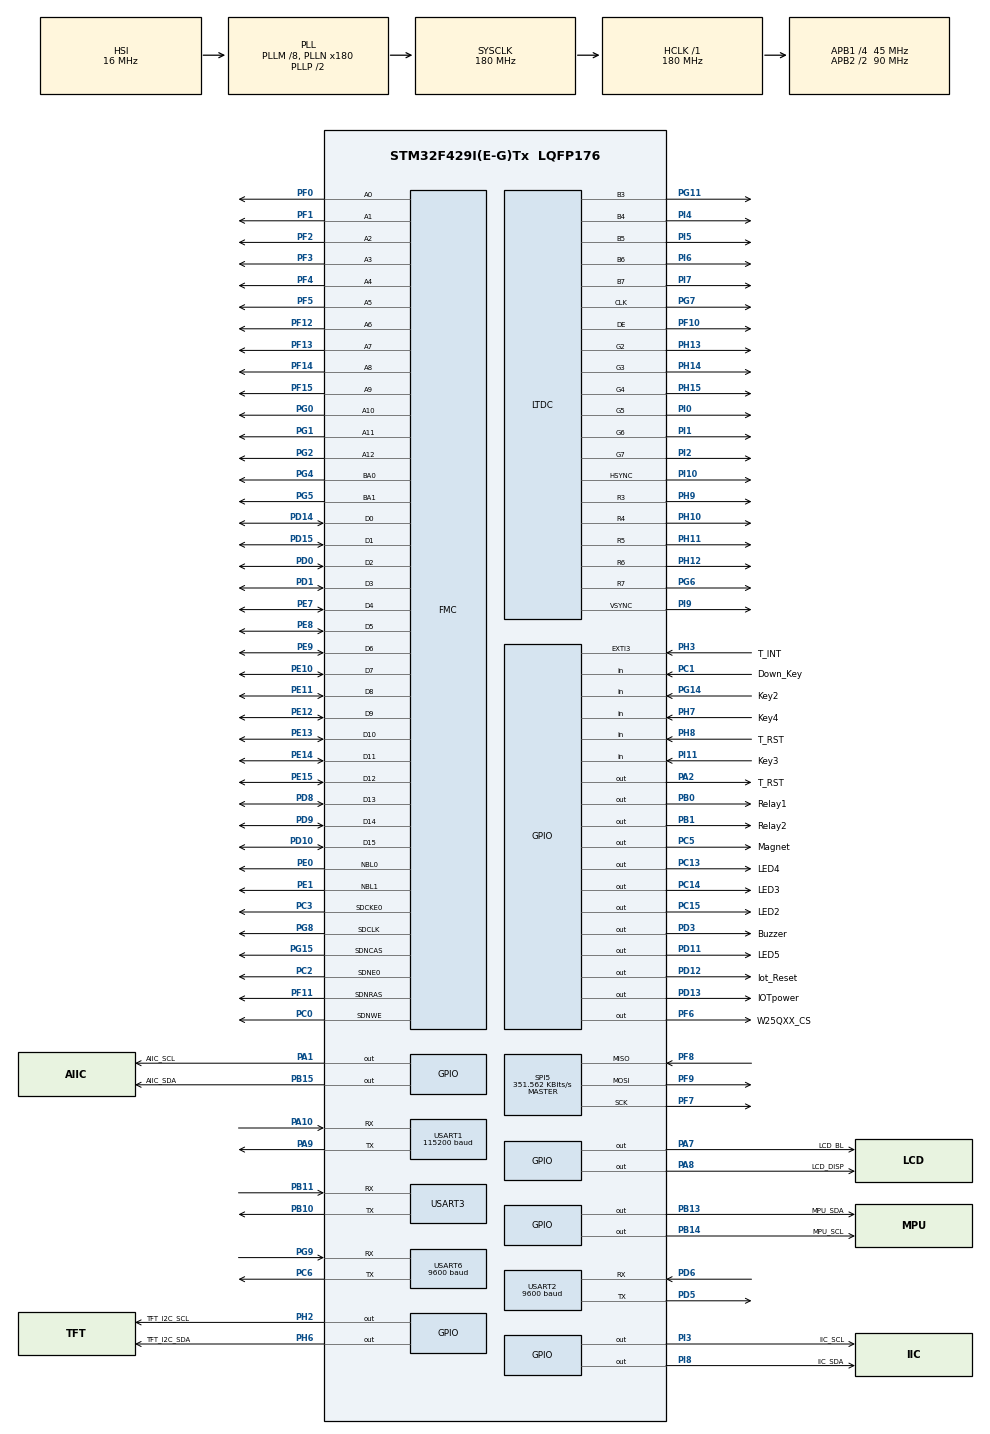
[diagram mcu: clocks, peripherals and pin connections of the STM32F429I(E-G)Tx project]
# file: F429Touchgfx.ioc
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DMA2D.ColorMode=DMA2D_OUTPUT_RGB565
DMA2D.Mode=DMA2D_R2M
Dma.Request0=USART3_RX
Dma.Request1=USART6_RX
Dma.USART3_RX.0.Direction=DMA_PERIPH_TO_MEMORY
Dma.USART3_RX.0.FIFOMode=DMA_FIFOMODE_DISABLE
Dma.USART3_RX.0.Instance=DMA1_Stream1
Dma.USART3_RX.0.MemDataAlignment=DMA_MDATAALIGN_BYTE
Dma.USART3_RX.0.MemInc=DMA_MINC_ENABLE
Dma.USART3_RX.0.Mode=DMA_NORMAL
Dma.USART3_RX.0.PeriphDataAlignment=DMA_PDATAALIGN_BYTE
Dma.USART3_RX.0.PeriphInc=DMA_PINC_DISABLE
Dma.USART3_RX.0.Priority=DMA_PRIORITY_LOW
Dma.USART6_RX.1.Direction=DMA_PERIPH_TO_MEMORY
Dma.USART6_RX.1.FIFOMode=DMA_FIFOMODE_DISABLE
Dma.USART6_RX.1.Instance=DMA2_Stream1
Dma.USART6_RX.1.MemDataAlignment=DMA_MDATAALIGN_BYTE
Dma.USART6_RX.1.MemInc=DMA_MINC_ENABLE
Dma.USART6_RX.1.Mode=DMA_NORMAL
Dma.USART6_RX.1.PeriphDataAlignment=DMA_PDATAALIGN_BYTE
Dma.USART6_RX.1.PeriphInc=DMA_PINC_DISABLE
Dma.USART6_RX.1.Priority=DMA_PRIORITY_LOW
FMC.CASLatency1=FMC_SDRAM_CAS_LATENCY_3
FMC.ColumnBitsNumber1=FMC_SDRAM_COLUMN_BITS_NUM_9
FMC.ExitSelfRefreshDelay1=8
FMC.LoadToActiveDelay1=2
FMC.RCDDelay1=2
FMC.RPDelay1=2
FMC.RPDelay2=2
FMC.ReadBurst1=FMC_SDRAM_RBURST_ENABLE
FMC.ReadBurst2=FMC_SDRAM_RBURST_ENABLE
FMC.ReadPipeDelay1=FMC_SDRAM_RPIPE_DELAY_1
FMC.ReadPipeDelay2=FMC_SDRAM_RPIPE_DELAY_1
FMC.RowCycleDelay1=6
FMC.RowCycleDelay2=6
FMC.SDClockPeriod1=FMC_SDRAM_CLOCK_PERIOD_2
FMC.SDClockPeriod2=FMC_SDRAM_CLOCK_PERIOD_2
FMC.SelfRefreshTime1=6
FMC.WriteRecoveryTime1=4
FREERTOS.Tasks01=defaultTask,0,2048,StartDefaultTask,Default,NULL,Dynamic,NULL,NULL;ATParse,-2,512,StartATParse,Default,NULL,Dynamic,NULL,NULL;ATFram,0,256,StartATFram,Default,NULL,Dynamic,NULL,NULL;ATSend,-2,256,StartATSend,Default,NULL,Dynamic,NULL,NULL;SensorCollect,-2,128,StartSensorCollect,Default,NULL,Dynamic,NULL,NULL
LTDC.ActiveH=480
LTDC.ActiveW=800
LTDC.Alpha_L0=0xff
LTDC.FBStartAdress_L0=0xc0000000
LTDC.HBP=88
LTDC.HFP=40
LTDC.HSync=48
LTDC.ImageHeight_L0=480
LTDC.ImageWidth_L0=800
LTDC.Layers=0
LTDC.PixelFormat_L0=LTDC_PIXEL_FORMAT_RGB565
LTDC.VBP=32
LTDC.VFP=13
LTDC.VSync=3
LTDC.WindowX1_L0=800
LTDC.WindowY1_L0=480
Mcu.Family=STM32F4
Mcu.Name=STM32F429I(E-G)Tx
Mcu.Package=LQFP176
NVIC.DMA1_Stream1_IRQn=true\:5\:0\:true\:false\:true\:false\:false\:true
NVIC.DMA2D_IRQn=true\:5\:0\:true\:false\:true\:false\:true\:true
NVIC.DMA2_Stream1_IRQn=true\:4\:0\:true\:false\:true\:false\:false\:true
NVIC.EXTI3_IRQn=true\:5\:0\:true\:false\:true\:false\:true\:true
NVIC.FLASH_IRQn=true\:5\:0\:true\:false\:true\:false\:true\:true
NVIC.FMC_IRQn=true\:5\:0\:true\:false\:true\:false\:true\:true
NVIC.FPU_IRQn=true\:5\:0\:true\:false\:true\:false\:false\:false
NVIC.LTDC_ER_IRQn=true\:6\:0\:true\:false\:true\:false\:true\:true
NVIC.LTDC_IRQn=true\:6\:0\:true\:false\:true\:false\:true\:true
NVIC.PVD_IRQn=true\:5\:0\:true\:false\:true\:false\:true\:true
NVIC.PriorityGroup=NVIC_PRIORITYGROUP_4
NVIC.RCC_IRQn=true\:5\:0\:true\:false\:true\:false\:false\:false
NVIC.SPI5_IRQn=true\:5\:0\:true\:false\:true\:false\:true\:true
NVIC.TIM1_UP_TIM10_IRQn=true\:0\:0\:false\:false\:true\:false\:false\:true
NVIC.TIM8_UP_TIM13_IRQn=true\:5\:0\:false\:false\:true\:true\:true\:true
NVIC.TimeBase=TIM1_UP_TIM10_IRQn
NVIC.TimeBaseIP=TIM1
NVIC.USART1_IRQn=true\:6\:0\:true\:false\:true\:false\:true\:true
NVIC.USART2_IRQn=true\:6\:0\:true\:false\:true\:false\:true\:true
NVIC.USART3_IRQn=true\:6\:0\:true\:false\:true\:false\:true\:true
NVIC.USART6_IRQn=true\:6\:0\:true\:false\:true\:false\:true\:true
PA1.GPIO_Label=AIIC_SCL
PA1.GPIO_PuPd=GPIO_PULLUP
PA1.GPIO_Speed=GPIO_SPEED_FREQ_HIGH
PA1.PinState=GPIO_PIN_SET
PA1.Signal=GPIO_Output
PA10.Mode=Asynchronous
PA10.Signal=USART1_RX
PA13.Mode=Serial_Wire
PA13.Signal=SYS_JTMS-SWDIO
PA14.Mode=Serial_Wire
PA14.Signal=SYS_JTCK-SWCLK
PA2.GPIO_Label=T_RST
PA2.GPIO_PuPd=GPIO_PULLUP
PA2.PinState=GPIO_PIN_SET
PA2.Signal=GPIO_Output
PA7.GPIO_Label=LCD_BL
PA7.GPIO_PuPd=GPIO_PULLUP
PA7.PinState=GPIO_PIN_SET
PA7.Signal=GPIO_Output
PA8.GPIO_Label=LCD_DISP
PA8.GPIO_PuPd=GPIO_PULLUP
PA8.PinState=GPIO_PIN_SET
PA8.Signal=GPIO_Output
PA9.Mode=Asynchronous
PA9.Signal=USART1_TX
PB0.GPIO_Label=Relay1
PB0.PinState=GPIO_PIN_SET
PB0.Signal=GPIO_Output
PB1.GPIO_Label=Relay2
PB1.PinState=GPIO_PIN_SET
PB1.Signal=GPIO_Output
PB10.Mode=Asynchronous
PB10.Signal=USART3_TX
PB11.GPIO_PuPd=GPIO_PULLUP
PB11.Mode=Asynchronous
PB11.Signal=USART3_RX
PB13.GPIO_Label=MPU_SDA
PB13.GPIO_PuPd=GPIO_PULLUP
PB13.PinState=GPIO_PIN_SET
PB13.Signal=GPIO_Output
PB14.GPIO_Label=MPU_SCL
PB14.GPIO_PuPd=GPIO_PULLUP
PB14.PinState=GPIO_PIN_SET
PB14.Signal=GPIO_Output
PB15.GPIO_Label=AIIC_SDA
PB15.GPIO_PuPd=GPIO_PULLUP
PB15.PinState=GPIO_PIN_SET
PB15.Signal=GPIO_Output
PC0.Signal=FMC_SDNWE
PC1.GPIO_Label=Down_Key
PC1.GPIO_PuPd=GPIO_PULLUP
PC1.Signal=GPIO_Input
PC13.GPIO_Label=LED4
PC13.GPIO_PuPd=GPIO_PULLUP
PC13.PinState=GPIO_PIN_SET
PC13.Signal=GPIO_Output
PC14/OSC32_IN.GPIO_Label=LED3
PC14/OSC32_IN.GPIO_PuPd=GPIO_PULLUP
PC14/OSC32_IN.PinState=GPIO_PIN_SET
PC14/OSC32_IN.Signal=GPIO_Output
PC15/OSC32_OUT.GPIO_Label=LED2
PC15/OSC32_OUT.GPIO_PuPd=GPIO_PULLUP
PC15/OSC32_OUT.PinState=GPIO_PIN_SET
PC15/OSC32_OUT.Signal=GPIO_Output
PC2.Mode=SdramChipSelect1_1
PC2.Signal=FMC_SDNE0
PC3.Mode=SdramChipSelect1_1
PC3.Signal=FMC_SDCKE0
PC5.GPIO_Label=Magnet
PC5.GPIO_PuPd=GPIO_PULLDOWN
PC5.PinState=GPIO_PIN_RESET
PC5.Signal=GPIO_Output
PC6.Mode=Asynchronous
PC6.Signal=USART6_TX
PD0.Signal=FMC_D2_DA2
PD1.Signal=FMC_D3_DA3
PD10.Signal=FMC_D15_DA15
PD11.GPIO_Label=LED5
PD11.GPIO_PuPd=GPIO_PULLUP
PD11.PinState=GPIO_PIN_SET
PD11.Signal=GPIO_Output
PD12.GPIO_Label=Iot_Reset
PD12.GPIO_PuPd=GPIO_PULLUP
PD12.PinState=GPIO_PIN_SET
PD12.Signal=GPIO_Output
PD13.GPIO_Label=IOTpower
PD13.GPIO_PuPd=GPIO_PULLUP
PD13.PinState=GPIO_PIN_SET
PD13.Signal=GPIO_Output
PD14.Signal=FMC_D0_DA0
PD15.Signal=FMC_D1_DA1
PD3.GPIO_Label=Buzzer
PD3.GPIO_PuPd=GPIO_PULLUP
PD3.Signal=GPIO_Output
PD5.Mode=Asynchronous
PD5.Signal=USART2_TX
PD6.GPIO_PuPd=GPIO_PULLUP
PD6.Mode=Asynchronous
PD6.Signal=USART2_RX
PD8.Signal=FMC_D13_DA13
PD9.Signal=FMC_D14_DA14
PE0.Signal=FMC_NBL0
PE1.Signal=FMC_NBL1
PE10.Signal=FMC_D7_DA7
PE11.Signal=FMC_D8_DA8
PE12.Signal=FMC_D9_DA9
PE13.Signal=FMC_D10_DA10
PE14.Signal=FMC_D11_DA11
PE15.Signal=FMC_D12_DA12
PE7.Signal=FMC_D4_DA4
PE8.Signal=FMC_D5_DA5
PE9.Signal=FMC_D6_DA6
PF0.Signal=FMC_A0
PF1.Signal=FMC_A1
PF10.Mode=RGB565
PF10.Signal=LTDC_DE
PF11.Signal=FMC_SDNRAS
PF12.Signal=FMC_A6
PF13.Signal=FMC_A7
PF14.Signal=FMC_A8
PF15.Signal=FMC_A9
PF2.Signal=FMC_A2
PF3.Signal=FMC_A3
PF4.Signal=FMC_A4
PF5.Signal=FMC_A5
PF6.GPIO_Label=W25QXX_CS
PF6.GPIO_PuPd=GPIO_PULLUP
PF6.GPIO_Speed=GPIO_SPEED_FREQ_HIGH
PF6.Signal=GPIO_Output
PF7.Mode=Full_Duplex_Master
PF7.Signal=SPI5_SCK
PF8.Mode=Full_Duplex_Master
PF8.Signal=SPI5_MISO
PF9.Mode=Full_Duplex_Master
PF9.Signal=SPI5_MOSI
PG0.Signal=FMC_A10
PG1.Signal=FMC_A11
PG11.Mode=RGB565
PG11.Signal=LTDC_B3
PG14.GPIO_Label=Key2
PG14.GPIO_PuPd=GPIO_PULLUP
PG14.Signal=GPIO_Input
PG15.Signal=FMC_SDNCAS
PG2.Signal=FMC_A12
PG4.Signal=FMC_A14_BA0
PG5.Signal=FMC_A15_BA1
PG6.Mode=RGB565
PG6.Signal=LTDC_R7
PG7.Mode=RGB565
PG7.Signal=LTDC_CLK
PG8.Signal=FMC_SDCLK
PG9.GPIO_PuPd=GPIO_PULLUP
PG9.Mode=Asynchronous
PG9.Signal=USART6_RX
PH0/OSC_IN.Mode=HSE-External-Oscillator
PH0/OSC_IN.Signal=RCC_OSC_IN
PH1/OSC_OUT.Mode=HSE-External-Oscillator
PH1/OSC_OUT.Signal=RCC_OSC_OUT
PH10.Mode=RGB565
PH10.Signal=LTDC_R4
PH11.Mode=RGB565
PH11.Signal=LTDC_R5
PH12.Mode=RGB565
PH12.Signal=LTDC_R6
PH13.Mode=RGB565
PH13.Signal=LTDC_G2
PH14.Mode=RGB565
PH14.Signal=LTDC_G3
PH15.Mode=RGB565
PH15.Signal=LTDC_G4
PH2.GPIO_Label=TFT_I2C_SCL
PH2.GPIO_PuPd=GPIO_PULLUP
PH2.PinState=GPIO_PIN_SET
PH2.Signal=GPIO_Output
PH3.GPIO_Label=T_INT
PH3.Signal=GPXTI3
PH6.GPIO_Label=TFT_I2C_SDA
PH6.GPIO_PuPd=GPIO_PULLUP
PH6.PinState=GPIO_PIN_SET
PH6.Signal=GPIO_Output
PH7.GPIO_Label=Key4
PH7.GPIO_PuPd=GPIO_PULLUP
PH7.Signal=GPIO_Input
PH8.GPIO_Label=T_RST
PH8.GPIO_PuPd=GPIO_PULLUP
PH8.Signal=GPIO_Input
PH9.Mode=RGB565
PH9.Signal=LTDC_R3
PI0.Mode=RGB565
PI0.Signal=LTDC_G5
PI1.Mode=RGB565
PI1.Signal=LTDC_G6
PI10.Mode=RGB565
PI10.Signal=LTDC_HSYNC
PI11.GPIO_Label=Key3
PI11.GPIO_PuPd=GPIO_PULLUP
PI11.Signal=GPIO_Input
PI2.Mode=RGB565
PI2.Signal=LTDC_G7
PI3.GPIO_Label=IIC_SCL
PI3.GPIO_PuPd=GPIO_PULLUP
PI3.PinState=GPIO_PIN_SET
PI3.Signal=GPIO_Output
PI4.Mode=RGB565
PI4.Signal=LTDC_B4
PI5.Mode=RGB565
PI5.Signal=LTDC_B5
PI6.Mode=RGB565
PI6.Signal=LTDC_B6
PI7.Mode=RGB565
PI7.Signal=LTDC_B7
PI8.GPIO_Label=IIC_SDA
PI8.GPIO_PuPd=GPIO_PULLUP
PI8.PinState=GPIO_PIN_SET
PI8.Signal=GPIO_Output
PI9.Mode=RGB565
PI9.Signal=LTDC_VSYNC
ProjectManager.HeapSize=0x200
ProjectManager.StackSize=0x400
ProjectManager.TargetToolchain=MDK-ARM V5.27
RCC.48MHZClocksFreq_Value=90000000
RCC.AHBFreq_Value=180000000
RCC.APB1CLKDivider=RCC_HCLK_DIV4
RCC.APB1Freq_Value=45000000
RCC.APB1TimFreq_Value=90000000
RCC.APB2CLKDivider=RCC_HCLK_DIV2
RCC.APB2Freq_Value=90000000
RCC.APB2TimFreq_Value=180000000
RCC.CortexFreq_Value=180000000
RCC.HCLKFreq_Value=180000000
RCC.HSE_VALUE=25000000
RCC.HSI_VALUE=16000000
RCC.LSE_VALUE=32768
RCC.PLLM=8
RCC.PLLN=180
RCC.PLLSAIN=50
RCC.SYSCLKFreq_VALUE=180000000
RCC.SYSCLKSource=RCC_SYSCLKSOURCE_PLLCLK
RCC.VCOOutputFreq_Value=360000000
SH.FMC_A0.0=FMC_A0,13b-sda1
SH.FMC_A1.0=FMC_A1,13b-sda1
SH.FMC_A10.0=FMC_A10,13b-sda1
SH.FMC_A11.0=FMC_A11,13b-sda1
SH.FMC_A12.0=FMC_A12,13b-sda1
SH.FMC_A14_BA0.0=FMC_BA0,FourSdramBanks1
SH.FMC_A15_BA1.0=FMC_BA1,FourSdramBanks1
SH.FMC_A2.0=FMC_A2,13b-sda1
SH.FMC_A3.0=FMC_A3,13b-sda1
SH.FMC_A4.0=FMC_A4,13b-sda1
SH.FMC_A5.0=FMC_A5,13b-sda1
SH.FMC_A6.0=FMC_A6,13b-sda1
SH.FMC_A7.0=FMC_A7,13b-sda1
SH.FMC_A8.0=FMC_A8,13b-sda1
SH.FMC_A9.0=FMC_A9,13b-sda1
SH.FMC_D0_DA0.0=FMC_D0,sd-16b-d1
SH.FMC_D10_DA10.0=FMC_D10,sd-16b-d1
SH.FMC_D11_DA11.0=FMC_D11,sd-16b-d1
SH.FMC_D12_DA12.0=FMC_D12,sd-16b-d1
SH.FMC_D13_DA13.0=FMC_D13,sd-16b-d1
SH.FMC_D14_DA14.0=FMC_D14,sd-16b-d1
SH.FMC_D15_DA15.0=FMC_D15,sd-16b-d1
SH.FMC_D1_DA1.0=FMC_D1,sd-16b-d1
SH.FMC_D2_DA2.0=FMC_D2,sd-16b-d1
SH.FMC_D3_DA3.0=FMC_D3,sd-16b-d1
SH.FMC_D4_DA4.0=FMC_D4,sd-16b-d1
SH.FMC_D5_DA5.0=FMC_D5,sd-16b-d1
SH.FMC_D6_DA6.0=FMC_D6,sd-16b-d1
SH.FMC_D7_DA7.0=FMC_D7,sd-16b-d1
SH.FMC_D8_DA8.0=FMC_D8,sd-16b-d1
SH.FMC_D9_DA9.0=FMC_D9,sd-16b-d1
SH.FMC_NBL0.0=FMC_NBL0,Sd2ByteEnable1
SH.FMC_NBL1.0=FMC_NBL1,Sd2ByteEnable1
SH.FMC_SDCLK.0=FMC_SDCLK,13b-sda1
SH.FMC_SDNCAS.0=FMC_SDNCAS,13b-sda1
SH.FMC_SDNRAS.0=FMC_SDNRAS,13b-sda1
SH.FMC_SDNWE.0=FMC_SDNWE,13b-sda1
SPI5.BaudRatePrescaler=SPI_BAUDRATEPRESCALER_256
SPI5.CLKPhase=SPI_PHASE_2EDGE
SPI5.CLKPolarity=SPI_POLARITY_HIGH
SPI5.CalculateBaudRate=351.562 KBits/s
SPI5.Direction=SPI_DIRECTION_2LINES
SPI5.Mode=SPI_MODE_MASTER
SPI5.VirtualType=VM_MASTER
STMicroelectronics.X-CUBE-TOUCHGFX.4.18.0.ApplicationCcGraphicsJjApplication=TouchGFXOoGenerator
STMicroelectronics.X-CUBE-TOUCHGFX.4.18.0.tgfx_address1=0xC0000000
STMicroelectronics.X-CUBE-TOUCHGFX.4.18.0.tgfx_address2=0xC00BB800
STMicroelectronics.X-CUBE-TOUCHGFX.4.18.0.tgfx_buffering_strategy=Double
STMicroelectronics.X-CUBE-TOUCHGFX.4.18.0.tgfx_display_interface=disp_ltdc
STMicroelectronics.X-CUBE-TOUCHGFX.4.18.0.tgfx_hardware_accelerator=dma_2d
STMicroelectronics.X-CUBE-TOUCHGFX.4.18.0.tgfx_location=By Address
STMicroelectronics.X-CUBE-TOUCHGFX.4.18.0.tgfx_vsync=vsync_ltdc
TIM13.AutoReloadPreload=TIM_AUTORELOAD_PRELOAD_ENABLE
TIM13.Period=10000-1
TIM13.Prescaler=9000-1
TIM14.AutoReloadPreload=TIM_AUTORELOAD_PRELOAD_ENABLE
TIM14.Prescaler=90-1
USART1.BaudRate=115200
USART1.VirtualMode=VM_ASYNC
USART2.BaudRate=9600
USART2.VirtualMode=VM_ASYNC
USART3.VirtualMode=VM_ASYNC
USART6.BaudRate=9600
USART6.VirtualMode=VM_ASYNC
VP_CRC_VS_CRC.Mode=CRC_Activate
VP_DMA2D_VS_DMA2D.Mode=DMA2D_Activate
VP_FREERTOS_VS_CMSIS_V1.Mode=CMSIS_V1
VP_STMicroelectronics.X-CUBE-TOUCHGFX_VS_GraphicsJjApplication_4.18.0.Mode=GraphicsJjApplication
VP_SYS_VS_tim1.Mode=TIM1
VP_TIM13_VS_ClockSourceINT.Mode=Enable_Timer
VP_TIM14_VS_ClockSourceINT.Mode=Enable_Timer
board=custom

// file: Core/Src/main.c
/* USER CODE BEGIN Header */
/**
  ******************************************************************************
  * @file           : main.c
  * @brief          : Main program body
  ******************************************************************************
  * @attention
  *
  * <h2><center>&copy; Copyright (c) 2021 STMicroelectronics.
  * All rights reserved.</center></h2>
  *
  * This software component is licensed by ST under Ultimate Liberty license
  * SLA0044, the "License"; You may not use this file except in compliance with
  * the License. You may obtain a copy of the License at:
  *                             www.st.com/SLA0044
  *
  ******************************************************************************
  */
/* USER CODE END Header */
#include "main.h"
#include "cmsis_os.h"
#include "crc.h"
#include "dma.h"
#include "dma2d.h"
#include "ltdc.h"
#include "spi.h"
#include "tim.h"
#include "usart.h"
#include "gpio.h"
#include "fmc.h"
#include "app_touchgfx.h"

/* USER CODE BEGIN Includes */
#include "gt1151q_iic_driver.h"
#include "w25qxx.h"
//#include "MY_Bm280_Bh1750.h"
#include "24c02.h"
#include "AT.h"
#include "cJSON.h"
#include "system.h"
#include "bh1750.h"
#include "bmp280.h"
#include "mpu6050.h"
#include "mk_dht11.h"
/* USER CODE END Includes */

void SystemClock_Config(void);
void MX_FREERTOS_Init(void);

int main(void)
{

  /* MCU Configuration--------------------------------------------------------*/

  /* Reset of all peripherals, Initializes the Flash interface and the Systick. */
  HAL_Init();

  /* Configure the system clock */
  SystemClock_Config();

  /* Initialize all configured peripherals */
  MX_GPIO_Init();
  MX_DMA_Init();
  MX_DMA2D_Init();
  MX_FMC_Init();
  MX_SPI5_Init();
  MX_USART1_UART_Init();
  MX_CRC_Init();
  MX_LTDC_Init();
  MX_USART2_UART_Init();
  MX_USART3_UART_Init();
  MX_USART6_UART_Init();
  MX_TIM14_Init();
  MX_TIM13_Init();
  MX_TouchGFX_Init();
  /* USER CODE BEGIN 2 */
	HAL_TIM_Base_Start_IT(&htim13);
	GT1151_Init();
	W25QXX_Init();

	bh1750_start();
	bmp280_start();
//	mpu6050_start();

	AT24CXX_Init();
  ATFormInit();

	while(AT24CXX_Check())	//检测不到24c02
	{
		printf("\r\n检测不到AT24C02：\r\n");
		delay_xms(500);
		HAL_GPIO_TogglePin(LED2_GPIO_Port, LED2_Pin);
	}

  /* USER CODE END 2 */

  /* Call init function for freertos objects (in freertos.c) */
  MX_FREERTOS_Init();
  /* Start scheduler */
  osKernelStart();

  /* We should never get here as control is now taken by the scheduler */
  /* Infinite loop */
  while (1)
  {

  }
}

void SystemClock_Config(void)
{
  RCC_OscInitTypeDef RCC_OscInitStruct = {0};
  RCC_ClkInitTypeDef RCC_ClkInitStruct = {0};
  RCC_PeriphCLKInitTypeDef PeriphClkInitStruct = {0};

  /** Configure the main internal regulator output voltage
  */
  __HAL_RCC_PWR_CLK_ENABLE();
  __HAL_PWR_VOLTAGESCALING_CONFIG(PWR_REGULATOR_VOLTAGE_SCALE1);
  /** Initializes the RCC Oscillators according to the specified parameters
  * in the RCC_OscInitTypeDef structure.
  */
  RCC_OscInitStruct.OscillatorType = RCC_OSCILLATORTYPE_HSI;
  RCC_OscInitStruct.HSIState = RCC_HSI_ON;
  RCC_OscInitStruct.HSICalibrationValue = RCC_HSICALIBRATION_DEFAULT;
  RCC_OscInitStruct.PLL.PLLState = RCC_PLL_ON;
  RCC_OscInitStruct.PLL.PLLSource = RCC_PLLSOURCE_HSI;
  RCC_OscInitStruct.PLL.PLLM = 8;
  RCC_OscInitStruct.PLL.PLLN = 180;
  RCC_OscInitStruct.PLL.PLLP = RCC_PLLP_DIV2;
  RCC_OscInitStruct.PLL.PLLQ = 4;
  if (HAL_RCC_OscConfig(&RCC_OscInitStruct) != HAL_OK)
  {
    Error_Handler();
  }
  /** Activate the Over-Drive mode
  */
  if (HAL_PWREx_EnableOverDrive() != HAL_OK)
  {
    Error_Handler();
  }
  /** Initializes the CPU, AHB and APB buses clocks
  */
  RCC_ClkInitStruct.ClockType = RCC_CLOCKTYPE_HCLK|RCC_CLOCKTYPE_SYSCLK
                              |RCC_CLOCKTYPE_PCLK1|RCC_CLOCKTYPE_PCLK2;
  RCC_ClkInitStruct.SYSCLKSource = RCC_SYSCLKSOURCE_PLLCLK;
  RCC_ClkInitStruct.AHBCLKDivider = RCC_SYSCLK_DIV1;
  RCC_ClkInitStruct.APB1CLKDivider = RCC_HCLK_DIV4;
  RCC_ClkInitStruct.APB2CLKDivider = RCC_HCLK_DIV2;

  if (HAL_RCC_ClockConfig(&RCC_ClkInitStruct, FLASH_LATENCY_5) != HAL_OK)
  {
    Error_Handler();
  }
  PeriphClkInitStruct.PeriphClockSelection = RCC_PERIPHCLK_LTDC;
  PeriphClkInitStruct.PLLSAI.PLLSAIN = 50;
  PeriphClkInitStruct.PLLSAI.PLLSAIR = 2;
  PeriphClkInitStruct.PLLSAIDivR = RCC_PLLSAIDIVR_2;
  if (HAL_RCCEx_PeriphCLKConfig(&PeriphClkInitStruct) != HAL_OK)
  {
    Error_Handler();
  }
}

/* USER CODE BEGIN 4 */
#pragma import(__use_no_semihosting)
//标准库需要的支持函数
struct __FILE
{
	int handle;
};
void _ttywrch(int ch)
{
//    ch=ch;
	HAL_UART_Transmit(&huart1, (uint8_t *)&ch, 1, HAL_MAX_DELAY);
}
FILE __stdout;
//定义_sys_exit()以避免使用半主机模式
void _sys_exit(int x)
{
	x = x;
}
int fputc(int ch ,FILE *F)
{
	HAL_UART_Transmit(&huart1, (uint8_t *)&ch, 1, HAL_MAX_DELAY); //按照配置自行修改huart1
	return ch;
}
/* USER CODE END 4 */

 /**
  * @brief  Period elapsed callback in non blocking mode
  * @note   This function is called  when TIM1 interrupt took place, inside
  * HAL_TIM_IRQHandler(). It makes a direct call to HAL_IncTick() to increment
  * a global variable "uwTick" used as application time base.
  * @param  htim : TIM handle
  * @retval None
  */
void HAL_TIM_PeriodElapsedCallback(TIM_HandleTypeDef *htim)
{
  if (htim->Instance == TIM1) {
    HAL_IncTick();
  }
  /* USER CODE BEGIN Callback 1 */
	if (htim->Instance == TIM13) {
		if (++time_seconds >= 60)
        {
            time_seconds = 0;
            if (++time_minutes >= 60)
            {
                time_minutes = 0;
                if (++time_hours >= 24)
                {
                    time_hours = 0;
                }
            }
        }
  }
  /* USER CODE END Callback 1 */
}

void Error_Handler(void)
{
  __disable_irq();
  while (1)
  {
  }
}

/************************ (C) COPYRIGHT STMicroelectronics *****END OF FILE****/

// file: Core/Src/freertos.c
/* USER CODE BEGIN Header */
/**
  ******************************************************************************
  * File Name          : freertos.c
  * Description        : Code for freertos applications
  ******************************************************************************
  * @attention
  *
  * <h2><center>&copy; Copyright (c) 2021 STMicroelectronics.
  * All rights reserved.</center></h2>
  *
  * This software component is licensed by ST under Ultimate Liberty license
  * SLA0044, the "License"; You may not use this file except in compliance with
  * the License. You may obtain a copy of the License at:
  *                             www.st.com/SLA0044
  *
  ******************************************************************************
  */
/* USER CODE END Header */

#include "FreeRTOS.h"
#include "task.h"
#include "main.h"
#include "cmsis_os.h"

/* USER CODE BEGIN Includes */
#include "stdio.h"
#include "AT.h"
//#include "MY_Bm280_Bh1750.h"
#include "cJSON.h"
#include "system.h"
/* USER CODE END Includes */

/* USER CODE BEGIN Variables */
char Cjsondata[250];
/* USER CODE END Variables */
osThreadId defaultTaskHandle;
osThreadId ATParseHandle;
osThreadId ATFramHandle;
osThreadId ATSendHandle;
osThreadId SensorCollectHandle;

void StartDefaultTask(void const * argument);
void StartATParse(void const * argument);
void StartATFram(void const * argument);
void StartATSend(void const * argument);
void StartSensorCollect(void const * argument);

void MX_FREERTOS_Init(void); /* (MISRA C 2004 rule 8.1) */

/* GetIdleTaskMemory prototype (linked to static allocation support) */
void vApplicationGetIdleTaskMemory( StaticTask_t **ppxIdleTaskTCBBuffer, StackType_t **ppxIdleTaskStackBuffer, uint32_t *pulIdleTaskStackSize );

/* USER CODE BEGIN GET_IDLE_TASK_MEMORY */
static StaticTask_t xIdleTaskTCBBuffer;
static StackType_t xIdleStack[configMINIMAL_STACK_SIZE];

void vApplicationGetIdleTaskMemory( StaticTask_t **ppxIdleTaskTCBBuffer, StackType_t **ppxIdleTaskStackBuffer, uint32_t *pulIdleTaskStackSize )
{
  *ppxIdleTaskTCBBuffer = &xIdleTaskTCBBuffer;
  *ppxIdleTaskStackBuffer = &xIdleStack[0];
  *pulIdleTaskStackSize = configMINIMAL_STACK_SIZE;
  /* place for user code */
}
/* USER CODE END GET_IDLE_TASK_MEMORY */

void MX_FREERTOS_Init(void) {

  /* Create the thread(s) */
  /* definition and creation of defaultTask */
  osThreadDef(defaultTask, StartDefaultTask, osPriorityNormal, 0, 2048);
  defaultTaskHandle = osThreadCreate(osThread(defaultTask), NULL);

  /* definition and creation of ATParse */
  osThreadDef(ATParse, StartATParse, osPriorityLow, 0, 512);
  ATParseHandle = osThreadCreate(osThread(ATParse), NULL);

  /* definition and creation of ATFram */
  osThreadDef(ATFram, StartATFram, osPriorityNormal, 0, 256);
  ATFramHandle = osThreadCreate(osThread(ATFram), NULL);

  /* definition and creation of ATSend */
  osThreadDef(ATSend, StartATSend, osPriorityLow, 0, 256);
  ATSendHandle = osThreadCreate(osThread(ATSend), NULL);

  /* definition and creation of SensorCollect */
  osThreadDef(SensorCollect, StartSensorCollect, osPriorityLow, 0, 128);
  SensorCollectHandle = osThreadCreate(osThread(SensorCollect), NULL);

}

void StartDefaultTask(void const * argument)
{
  /* USER CODE BEGIN StartDefaultTask */
	MX_TouchGFX_Process();
  /* Infinite loop */
  for(;;)
  {
    osDelay(100);
  }
  /* USER CODE END StartDefaultTask */
}

void StartATParse(void const * argument)
{
  /* USER CODE BEGIN StartATParse */
  /* Infinite loop */
  for(;;)
  {
    osDelay(100);
		if(uxQueueSpacesAvailable(ATcmdQueue)==10)//队列为空
		{
			if(xSemaphoreTake(ATSchRunSemaphore,( TickType_t ) 10)==pdTRUE) //获得互斥量:上锁
			{
//				PrintIotRxData();
					char *p=NULL;
					BaseType_t xResult;
					uint32_t RXDataLength=0;
					xResult=xSemaphoreTake(ATRXCplSemaphore,pdMS_TO_TICKS(1000));
					if(xResult != pdPASS)
					{
						xSemaphoreGive(ATSchRunSemaphore);/* 释放互斥量: 开锁 */
						continue;
					}
					else
					{
						printf("接收到数据\r\n");
					}
					RXDataLength=0;
					RXDataLength  = _UART_RXBUFFSIZE - __HAL_DMA_GET_COUNTER(&_UART_DMA_HANDLE);
					UartRXBuff[RXDataLength]='\0';
					__LOG("Receive Data(length = %d):%s\r\n",RXDataLength,UartRXBuff);

					p=strstr((char *)UartRXBuff,"items");
					if(p)
					{
						strcpy(Cjsondata,p+7);
						Cjsondata[strlen(Cjsondata)-3]='\0';//字符串末尾存在\r\n两个看不见的字符
						printf("THE JSON DATA IS: \r\n%s,数据长：%d\r\n",Cjsondata,strlen(Cjsondata));
						CJSON_analysis(Cjsondata);
					}

					__HAL_DMA_DISABLE(&_UART_DMA_HANDLE);

				  xSemaphoreGive(ATSchRunSemaphore);/* 释放互斥量: 开锁 */
			}
		}
//		printf("dht temp:%d hum:%d \r\n",dht_temperature,dht_humidty);
  }
  /* USER CODE END StartATParse */
}

void StartATFram(void const * argument)
{
  /* USER CODE BEGIN StartATFram */
	HAL_GPIO_WritePin(Iot_Reset_GPIO_Port,Iot_Reset_Pin,GPIO_PIN_RESET);		//复位
	osDelay(500);
	HAL_GPIO_WritePin(Iot_Reset_GPIO_Port,Iot_Reset_Pin,GPIO_PIN_SET);
	HAL_GPIO_WritePin(IOTpower_GPIO_Port,IOTpower_Pin,GPIO_PIN_RESET);      //开机
	osDelay(2200);
	HAL_GPIO_WritePin(IOTpower_GPIO_Port,IOTpower_Pin,GPIO_PIN_SET);

	printf("联网中...");
	while(strstr(UartRXBuff,"IP")==NULL)//等待设备联网
	{
		printf(".");
		osDelay(1000);
	}
	printf("\r\n联网成功!");
	PrintIotRxData();
  /* Infinite loop */
  for(;;)
  {
    ATCommandSendScheduler();
  }
  /* USER CODE END StartATFram */
}

void StartATSend(void const * argument)
{
  /* USER CODE BEGIN StartATSend */
	static char PubParam[400];
	char * jsonRes;

	ATCommandRegister(AT,EXEXCMD,NULL);
	ATCommandRegister(MQTTCFG,WRITECMD,"\"a1wocurZ0R0.iot-as-mqtt.cn-shanghai.aliyuncs.com\",1883,\"711382|securemode=3,signmethod=hmacsha1|\",\"60\",\"M5311_1382&a1wocurZ0R0\",\"A40C776AD48B66A8DB8A5EEE517625E2DB4501B4\",1");
	ATCommandRegister(MQTTOPEN,WRITECMD,"1,1,0,0,0");
	ATCommandRegister(MQTTSUB,WRITECMD,"/sys/a1wocurZ0R0/M5311_1382/thing/service/property/set");
	ATCommandRegister(CCLK,READCMD,NULL);
  /* Infinite loop */
  for(;;)
  {
		osDelay(10000);
		osDelay(10000);
		osDelay(10000);
		while(uxQueueSpacesAvailable(ATcmdQueue)!=10)//等待队列为空
		{
			osDelay(100);
		}
		cJSON* cjson_root = NULL;
		cJSON* cjson_params = NULL;
		cjson_root =  cJSON_CreateObject();
		cjson_params  =  cJSON_CreateObject();
		cJSON_AddNumberToObject(cjson_params,"CurrentTemperature",(float)(((int)(bmp280_temperature*100))/100));
		cJSON_AddNumberToObject(cjson_params,"CurrentHumidity",(uint32_t)dht_humidty);
		cJSON_AddNumberToObject(cjson_params,"LightLux",bh1750_lux);
		cJSON_AddNumberToObject(cjson_params,"Atmosphere",(uint32_t)bmp280_pressure);
//		cJSON_AddNumberToObject(cjson_params,"lie",34);
		cJSON_AddItemToObject(cjson_root,"params",cjson_params);
		jsonRes = cJSON_Print(cjson_root);
		sprintf(PubParam,"\"/sys/a1wocurZ0R0/M5311_1382/thing/event/property/post\",1,1,0,0,\"%s\"",jsonRes);
//			printf("上报数据：%s\n\r",jsonRes);
//			printf("AT+MQTTPUB=\"/sys/a1wocurZ0R0/M5311_1382/thing/event/property/post\",1,1,0,0,\"%s\"\r\n",jsonRes);
		cJSON_Delete(cjson_root);				//删除Json数组
		vPortFree(jsonRes);							//释放内存不释放就会出错

//		__LOG("上报数据：%s\r\n",PubParam);
//			IOT_printf("%s\r\n",PubParam);
		ATCommandRegister(MQTTPUB,WRITECMD,PubParam);

  }
  /* USER CODE END StartATSend */
}

void StartSensorCollect(void const * argument)
{
  /* USER CODE BEGIN StartSensorCollect */
  /* Infinite loop */
  for(;;)
  {
		update_sensor_value();
    osDelay(1000);
  }
  /* USER CODE END StartSensorCollect */
}

/************************ (C) COPYRIGHT STMicroelectronics *****END OF FILE****/
